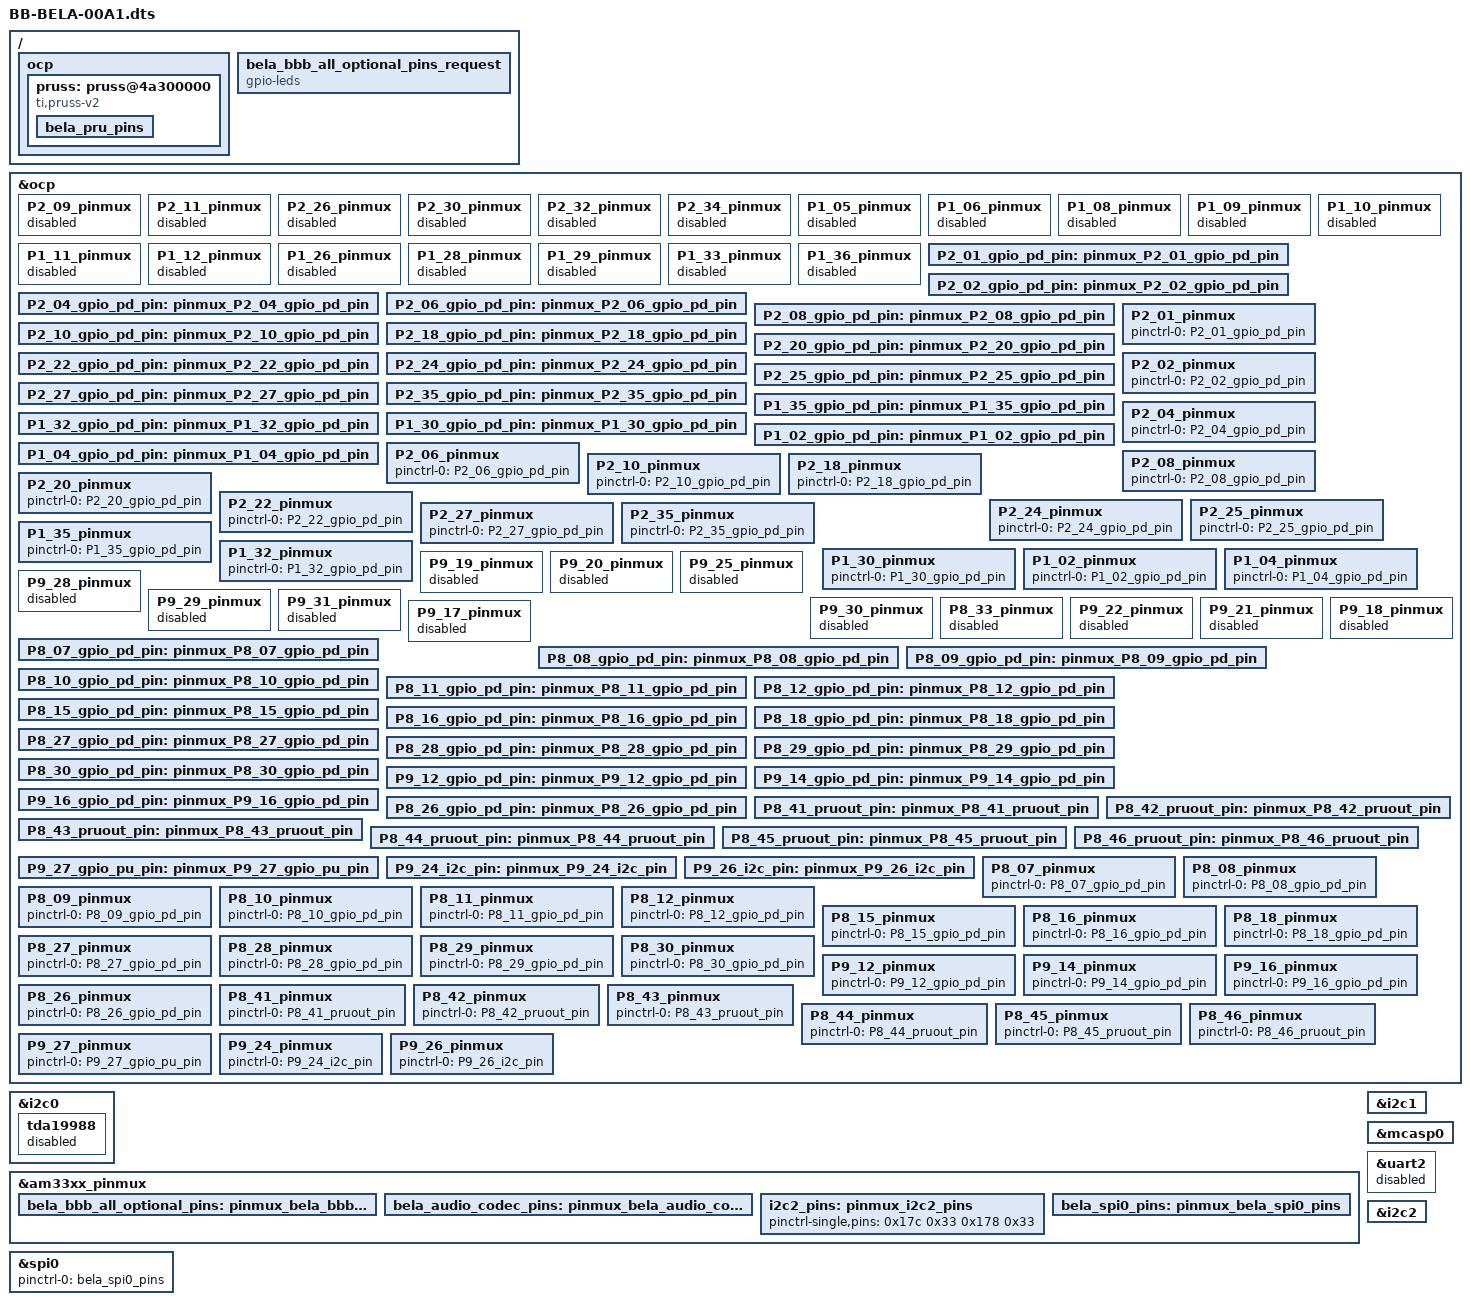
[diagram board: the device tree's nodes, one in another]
/*
 * Copyright (C) 2017-2018 <insert>
 *
 * This program is free software; you can redistribute it and/or modify
 * it under the terms of the GNU General Public License version 2 as
 * published by the Free Software Foundation.
 */

/dts-v1/;
/plugin/;

#include <dt-bindings/gpio/gpio.h>
#include <dt-bindings/pinctrl/am33xx.h>

/ {
	/*
	 * Free up the pins used by the cape from the pinmux helpers and set defaults
	 */
	fragment@0 {
		target = <&ocp>;
		__overlay__ {
			// PocketBeagle (has cape-universal built-in). If we
			// are on BBB, this fragment gets loaded but does
			// nothing.
			P2_09_pinmux { status = "disabled"; }; 
			P2_11_pinmux { status = "disabled"; }; 
			P2_26_pinmux { status = "disabled"; };
			P2_30_pinmux { status = "disabled"; };
			P2_32_pinmux { status = "disabled"; };
			P2_34_pinmux { status = "disabled"; };
			P1_05_pinmux { status = "disabled"; };
			P1_06_pinmux { status = "disabled"; };
			P1_08_pinmux { status = "disabled"; };
			P1_09_pinmux { status = "disabled"; };
			P1_10_pinmux { status = "disabled"; };
			P1_11_pinmux { status = "disabled"; };
			P1_12_pinmux { status = "disabled"; };
			P1_26_pinmux { status = "disabled"; };
			P1_28_pinmux { status = "disabled"; };
			P1_29_pinmux { status = "disabled"; };
			P1_33_pinmux { status = "disabled"; };
			P1_36_pinmux { status = "disabled"; };

			// these definitions copied from am335x-pocketbeagle-common.dtsi and are provided 
			// to avoid missing symbols when running on BBB
			P2_01_gpio_pd_pin: pinmux_P2_01_gpio_pd_pin { pinctrl-single,pins = <
				AM33XX_IOPAD(0x0848, PIN_OUTPUT_PULLDOWN | INPUT_EN | MUX_MODE7) >; };	/* gpmc_a2.gpio1_18 */
			P2_02_gpio_pd_pin: pinmux_P2_02_gpio_pd_pin { pinctrl-single,pins = <
				AM33XX_IOPAD(0x086c, PIN_OUTPUT_PULLDOWN | INPUT_EN | MUX_MODE7) >; };	/* gpmc_a11.gpio1_27 */
			P2_04_gpio_pd_pin: pinmux_P2_04_gpio_pd_pin { pinctrl-single,pins = <
				AM33XX_IOPAD(0x0868, PIN_OUTPUT_PULLDOWN | INPUT_EN | MUX_MODE7) >; };	/* gpmc_a10.gpio1_26 */
			P2_06_gpio_pd_pin: pinmux_P2_06_gpio_pd_pin { pinctrl-single,pins = <
				AM33XX_IOPAD(0x0864, PIN_OUTPUT_PULLDOWN | INPUT_EN | MUX_MODE7) >; };	/* gpmc_a9.gpio1_25 */
			P2_08_gpio_pd_pin: pinmux_P2_08_gpio_pd_pin { pinctrl-single,pins = <
				AM33XX_IOPAD(0x0878, PIN_OUTPUT_PULLDOWN | INPUT_EN | MUX_MODE7) >; };	/* gpmc_be1n.gpio1_28 */
			P2_10_gpio_pd_pin: pinmux_P2_10_gpio_pd_pin { pinctrl-single,pins = <
				AM33XX_IOPAD(0x0850, PIN_OUTPUT_PULLDOWN | INPUT_EN | MUX_MODE7) >; };	/* gpmc_a4.gpio1_20 */
			P2_18_gpio_pd_pin: pinmux_P2_18_gpio_pd_pin { pinctrl-single,pins = <
				AM33XX_IOPAD(0x083c, PIN_OUTPUT_PULLDOWN | INPUT_EN | MUX_MODE7) >; };	/* gpmc_ad15.gpio1_15 */
			P2_20_gpio_pd_pin: pinmux_P2_20_gpio_pd_pin { pinctrl-single,pins = <
				AM33XX_IOPAD(0x0888, PIN_OUTPUT_PULLDOWN | INPUT_EN | MUX_MODE7) >; };	/* gpmc_csn3.gpio2_0 */
			P2_22_gpio_pd_pin: pinmux_P2_22_gpio_pd_pin { pinctrl-single,pins = <
				AM33XX_IOPAD(0x0838, PIN_OUTPUT_PULLDOWN | INPUT_EN | MUX_MODE7) >; };	/* gpmc_ad14.gpio1_14 */
			P2_24_gpio_pd_pin: pinmux_P2_24_gpio_pd_pin { pinctrl-single,pins = <
				AM33XX_IOPAD(0x0830, PIN_OUTPUT_PULLDOWN | INPUT_EN | MUX_MODE7) >; };	/* gpmc_ad12.gpio1_12 */
			P2_25_gpio_pd_pin: pinmux_P2_25_gpio_pd_pin { pinctrl-single,pins = <
				AM33XX_IOPAD(0x096c, PIN_OUTPUT_PULLDOWN | INPUT_EN | MUX_MODE7) >; };	/* uart0_rtsn.gpio1_9 */
			P2_27_gpio_pd_pin: pinmux_P2_27_gpio_pd_pin { pinctrl-single,pins = <
				AM33XX_IOPAD(0x0968, PIN_OUTPUT_PULLDOWN | INPUT_EN | MUX_MODE7) >; };	/* uart0_ctsn.gpio1_8 */
			P2_35_gpio_pd_pin: pinmux_P2_35_gpio_pd_pin { pinctrl-single,pins = <
				AM33XX_IOPAD(0x08e0, PIN_OUTPUT_PULLDOWN | INPUT_EN | MUX_MODE7) >; };	/* lcd_vsync.gpio2_22 */
			P1_35_gpio_pd_pin: pinmux_P1_35_gpio_pd_pin { pinctrl-single,pins = <
				AM33XX_IOPAD(0x08e8, PIN_OUTPUT_PULLDOWN | INPUT_EN | MUX_MODE7) >; };	/* lcd_pclk.gpio2_24 */
			P1_32_gpio_pd_pin: pinmux_P1_32_gpio_pd_pin { pinctrl-single,pins = <
				AM33XX_IOPAD(0x0970, PIN_OUTPUT_PULLDOWN | INPUT_EN | MUX_MODE7) >; };	/* uart0_rxd.gpio1_10 */
			P1_30_gpio_pd_pin: pinmux_P1_30_gpio_pd_pin { pinctrl-single,pins = <
				AM33XX_IOPAD(0x0974, PIN_OUTPUT_PULLDOWN | INPUT_EN | MUX_MODE7) >; };	/* uart0_txd.gpio1_11 */
			P1_02_gpio_pd_pin: pinmux_P1_02_gpio_pd_pin { pinctrl-single,pins = <
				AM33XX_IOPAD(0x08e4, PIN_OUTPUT_PULLDOWN | INPUT_EN | MUX_MODE7) >; };	/* lcd_hsync.gpio2_23 */
			P1_04_gpio_pd_pin: pinmux_P1_04_gpio_pd_pin { pinctrl-single,pins = <
				AM33XX_IOPAD(0x08ec, PIN_OUTPUT_PULLDOWN | INPUT_EN | MUX_MODE7) >; };	/* lcd_ac_bias_en.gpio2_25 */

			// Bela digitals
			P2_01_pinmux{ pinctrl-0 = <&P2_01_gpio_pd_pin>; };
			P2_02_pinmux{ pinctrl-0 = <&P2_02_gpio_pd_pin>; };
			P2_04_pinmux{ pinctrl-0 = <&P2_04_gpio_pd_pin>; };
			P2_06_pinmux{ pinctrl-0 = <&P2_06_gpio_pd_pin>; };
			P2_08_pinmux{ pinctrl-0 = <&P2_08_gpio_pd_pin>; };
			P2_10_pinmux{ pinctrl-0 = <&P2_10_gpio_pd_pin>; };
			P2_18_pinmux{ pinctrl-0 = <&P2_18_gpio_pd_pin>; };
			P2_20_pinmux{ pinctrl-0 = <&P2_20_gpio_pd_pin>; };
			P2_22_pinmux{ pinctrl-0 = <&P2_22_gpio_pd_pin>; };
			P2_24_pinmux{ pinctrl-0 = <&P2_24_gpio_pd_pin>; };
			P2_25_pinmux{ pinctrl-0 = <&P2_25_gpio_pd_pin>; };
			P2_27_pinmux{ pinctrl-0 = <&P2_27_gpio_pd_pin>; };
			P2_35_pinmux{ pinctrl-0 = <&P2_35_gpio_pd_pin>; };
			P1_35_pinmux{ pinctrl-0 = <&P1_35_gpio_pd_pin>; };
			P1_32_pinmux{ pinctrl-0 = <&P1_32_gpio_pd_pin>; };
			P1_30_pinmux{ pinctrl-0 = <&P1_30_gpio_pd_pin>; };

			// LEDs
			P1_02_pinmux{ pinctrl-0 = <&P1_02_gpio_pd_pin>; };
			P1_04_pinmux{ pinctrl-0 = <&P1_04_gpio_pd_pin>; };
		};
	};
	fragment@1 {
		target = <&ocp>;
		__overlay__ {
			// BeagleBone when cape-universal is loaded. If it is not loaded, this fragment loads but does nothing.
			// When cape-universal* is not loaded, these pins are all set in bela_bbb_all_optional_pins

			// These are fixed function so we disable config-pin
			// and hardcode them elsewhere.
			P9_19_pinmux { status = "disabled"; }; // i2c2_scl
			P9_20_pinmux { status = "disabled"; }; // i2c2_sda
			P9_25_pinmux { status = "disabled"; }; // mcasp0_ahclkx
			P9_28_pinmux { status = "disabled"; }; // mcasp0_axr2
			P9_29_pinmux { status = "disabled"; }; // mcasp0_fsx
			P9_31_pinmux { status = "disabled"; }; // mcasp0_ahclk
			P9_30_pinmux { status = "disabled"; }; // mcasp0_axr0
			P8_33_pinmux { status = "disabled"; }; // mcasp0_axr3

			P9_22_pinmux { status = "disabled"; }; /* spi0_sclk */
			P9_21_pinmux { status = "disabled"; }; /* spi0_d0 */
			P9_18_pinmux { status = "disabled"; }; /* spi0_d1 */
			P9_17_pinmux { status = "disabled"; }; // spi0_cs0

			// For the below, if cape-universal* is loaded, we set
			// here the default value, but users can override it
			// with config-pin.

			//These definitions are copied from
			//cape-universaln-00A0.dts and are provided to avoid
			//missing symbols when cape-universaln is not loaded

			P8_07_gpio_pd_pin: pinmux_P8_07_gpio_pd_pin { pinctrl-single,pins = <
				AM33XX_IOPAD(0x0890, PIN_OUTPUT_PULLDOWN | INPUT_EN | MUX_MODE7) >; };	/* gpmc_advn_ale.gpio2_2 */
			P8_08_gpio_pd_pin: pinmux_P8_08_gpio_pd_pin { pinctrl-single,pins = <
				AM33XX_IOPAD(0x0894, PIN_OUTPUT_PULLDOWN | INPUT_EN | MUX_MODE7) >; };	/* gpmc_oen_ren.gpio2_3 */
			P8_09_gpio_pd_pin: pinmux_P8_09_gpio_pd_pin { pinctrl-single,pins = <
				AM33XX_IOPAD(0x089c, PIN_OUTPUT_PULLDOWN | INPUT_EN | MUX_MODE7) >; };	/* gpmc_be0n_cle.gpio2_5 */
			P8_10_gpio_pd_pin: pinmux_P8_10_gpio_pd_pin { pinctrl-single,pins = <
				AM33XX_IOPAD(0x0898, PIN_OUTPUT_PULLDOWN | INPUT_EN | MUX_MODE7) >; };	/* gpmc_wen.gpio2_4 */
			P8_11_gpio_pd_pin: pinmux_P8_11_gpio_pd_pin { pinctrl-single,pins = <
				AM33XX_IOPAD(0x0834, PIN_OUTPUT_PULLDOWN | INPUT_EN | MUX_MODE7) >; };	/* gpmc_ad13.gpio1_13 */
			P8_12_gpio_pd_pin: pinmux_P8_12_gpio_pd_pin { pinctrl-single,pins = <
				AM33XX_IOPAD(0x0830, PIN_OUTPUT_PULLDOWN | INPUT_EN | MUX_MODE7) >; };	/* gpmc_ad12.gpio1_12 */
			P8_15_gpio_pd_pin: pinmux_P8_15_gpio_pd_pin { pinctrl-single,pins = <
				AM33XX_IOPAD(0x083c, PIN_OUTPUT_PULLDOWN | INPUT_EN | MUX_MODE7) >; };	/* gpmc_ad15.gpio1_15 */
			P8_16_gpio_pd_pin: pinmux_P8_16_gpio_pd_pin { pinctrl-single,pins = <
				AM33XX_IOPAD(0x0838, PIN_OUTPUT_PULLDOWN | INPUT_EN | MUX_MODE7) >; };	/* gpmc_ad14.gpio1_14 */
			P8_18_gpio_pd_pin: pinmux_P8_18_gpio_pd_pin { pinctrl-single,pins = <
				AM33XX_IOPAD(0x088c, PIN_OUTPUT_PULLDOWN | INPUT_EN | MUX_MODE7) >; };	/* gpmc_clk.gpio2_1 */
			P8_27_gpio_pd_pin: pinmux_P8_27_gpio_pd_pin { pinctrl-single,pins = <
				AM33XX_IOPAD(0x08e0, PIN_OUTPUT_PULLDOWN | INPUT_EN | MUX_MODE7) >; };	/* lcd_vsync.gpio2_22 */
			P8_28_gpio_pd_pin: pinmux_P8_28_gpio_pd_pin { pinctrl-single,pins = <
				AM33XX_IOPAD(0x08e8, PIN_OUTPUT_PULLDOWN | INPUT_EN | MUX_MODE7) >; };	/* lcd_pclk.gpio2_24 */
			P8_29_gpio_pd_pin: pinmux_P8_29_gpio_pd_pin { pinctrl-single,pins = <
				AM33XX_IOPAD(0x08e4, PIN_OUTPUT_PULLDOWN | INPUT_EN | MUX_MODE7) >; };	/* lcd_hsync.gpio2_23 */
			P8_30_gpio_pd_pin: pinmux_P8_30_gpio_pd_pin { pinctrl-single,pins = <
				AM33XX_IOPAD(0x08ec, PIN_OUTPUT_PULLDOWN | INPUT_EN | MUX_MODE7) >; };	/* lcd_ac_bias_en.gpio2_25 */
			P9_12_gpio_pd_pin: pinmux_P9_12_gpio_pd_pin { pinctrl-single,pins = <
				AM33XX_IOPAD(0x0878, PIN_OUTPUT_PULLDOWN | INPUT_EN | MUX_MODE7) >; };	/* gpmc_be1n.gpio1_28 */
			P9_14_gpio_pd_pin: pinmux_P9_14_gpio_pd_pin { pinctrl-single,pins = <
				AM33XX_IOPAD(0x0848, PIN_OUTPUT_PULLDOWN | INPUT_EN | MUX_MODE7) >; };	/* gpmc_a2.gpio1_18 */
			P9_16_gpio_pd_pin: pinmux_P9_16_gpio_pd_pin { pinctrl-single,pins = <
				AM33XX_IOPAD(0x084c, PIN_OUTPUT_PULLDOWN | INPUT_EN | MUX_MODE7) >; };	/* gpmc_a3.gpio1_19 */
			P8_26_gpio_pd_pin: pinmux_P8_26_gpio_pd_pin { pinctrl-single,pins = <
				AM33XX_IOPAD(0x087c, PIN_OUTPUT_PULLDOWN | INPUT_EN | MUX_MODE7) >; };	/* gpmc_csn0.gpio1_29 */
			P8_41_pruout_pin: pinmux_P8_41_pruout_pin { pinctrl-single,pins = <
				AM33XX_IOPAD(0x08b0, PIN_OUTPUT_PULLDOWN | INPUT_EN | MUX_MODE5) >; };	/* lcd_data4.pru1_out4 */
			P8_42_pruout_pin: pinmux_P8_42_pruout_pin { pinctrl-single,pins = <
				AM33XX_IOPAD(0x08b4, PIN_OUTPUT_PULLDOWN | INPUT_EN | MUX_MODE5) >; };	/* lcd_data5.pru1_out5 */
			P8_43_pruout_pin: pinmux_P8_43_pruout_pin { pinctrl-single,pins = <
				AM33XX_IOPAD(0x08a8, PIN_OUTPUT_PULLDOWN | INPUT_EN | MUX_MODE5) >; };	/* lcd_data2.pru1_out2 */
			P8_44_pruout_pin: pinmux_P8_44_pruout_pin { pinctrl-single,pins = <
				AM33XX_IOPAD(0x08ac, PIN_OUTPUT_PULLDOWN | INPUT_EN | MUX_MODE5) >; };	/* lcd_data3.pru1_out3 */
			P8_45_pruout_pin: pinmux_P8_45_pruout_pin { pinctrl-single,pins = <
				AM33XX_IOPAD(0x08a0, PIN_OUTPUT_PULLDOWN | INPUT_EN | MUX_MODE5) >; };	/* lcd_data0.pru1_out0 */
			P8_46_pruout_pin: pinmux_P8_46_pruout_pin { pinctrl-single,pins = <
				AM33XX_IOPAD(0x08a4, PIN_OUTPUT_PULLDOWN | INPUT_EN | MUX_MODE5) >; };	/* lcd_data1.pru1_out1 */
			P9_27_gpio_pu_pin: pinmux_P9_27_gpio_pu_pin { pinctrl-single,pins = <
				AM33XX_IOPAD(0x09a4, PIN_OUTPUT_PULLUP | INPUT_EN | MUX_MODE7) >; };	/* mcasp0_fsr.gpio3_19 */
			P9_24_i2c_pin: pinmux_P9_24_i2c_pin { pinctrl-single,pins = <
				AM33XX_IOPAD(0x0984, PIN_OUTPUT_PULLUP | INPUT_EN | MUX_MODE3) >; };	/* uart1_txd.i2c1_scl */
			P9_26_i2c_pin: pinmux_P9_26_i2c_pin { pinctrl-single,pins = <
				AM33XX_IOPAD(0x0980, PIN_OUTPUT_PULLUP | INPUT_EN | MUX_MODE3) >; };	/* uart1_rxd.i2c1_sda */

			// Bela digitals
			P8_07_pinmux { pinctrl-0 = <&P8_07_gpio_pd_pin>; };
			P8_08_pinmux { pinctrl-0 = <&P8_08_gpio_pd_pin>; };
			P8_09_pinmux { pinctrl-0 = <&P8_09_gpio_pd_pin>; };
			P8_10_pinmux { pinctrl-0 = <&P8_10_gpio_pd_pin>; };
			P8_11_pinmux { pinctrl-0 = <&P8_11_gpio_pd_pin>; };
			P8_12_pinmux { pinctrl-0 = <&P8_12_gpio_pd_pin>; };
			P8_15_pinmux { pinctrl-0 = <&P8_15_gpio_pd_pin>; };
			P8_16_pinmux { pinctrl-0 = <&P8_16_gpio_pd_pin>; };
			P8_18_pinmux { pinctrl-0 = <&P8_18_gpio_pd_pin>; };
			P8_27_pinmux { pinctrl-0 = <&P8_27_gpio_pd_pin>; };
			P8_28_pinmux { pinctrl-0 = <&P8_28_gpio_pd_pin>; };
			P8_29_pinmux { pinctrl-0 = <&P8_29_gpio_pd_pin>; };
			P8_30_pinmux { pinctrl-0 = <&P8_30_gpio_pd_pin>; };
			P9_12_pinmux { pinctrl-0 = <&P9_12_gpio_pd_pin>; };
			P9_14_pinmux { pinctrl-0 = <&P9_14_gpio_pd_pin>; };
			P9_16_pinmux { pinctrl-0 = <&P9_16_gpio_pd_pin>; };

			P8_26_pinmux { pinctrl-0 = <&P8_26_gpio_pd_pin>; }; // speaker mute pin
			P8_41_pinmux { pinctrl-0 = <&P8_41_pruout_pin>; }; // muxer clock
			P8_42_pinmux { pinctrl-0 = <&P8_42_pruout_pin>; }; // muxer clock
			P8_43_pinmux { pinctrl-0 = <&P8_43_pruout_pin>; }; // muxer clock
			P8_44_pinmux { pinctrl-0 = <&P8_44_pruout_pin>; }; // muxer clock
			P8_45_pinmux { pinctrl-0 = <&P8_45_pruout_pin>; }; // muxer clock
			P8_46_pinmux { pinctrl-0 = <&P8_46_pruout_pin>; }; // muxer clock
			P9_27_pinmux { pinctrl-0 = <&P9_27_gpio_pu_pin>; }; // Bela Button
			P9_24_pinmux { pinctrl-0 = <&P9_24_i2c_pin>; }; // i2c1_scl
			P9_26_pinmux { pinctrl-0 = <&P9_26_i2c_pin>; }; // i2c1_sda
		};
	};

	fragment@2 {
		// disable HDMI
		target = <&i2c0>;
		__overlay__ {
			tda19988 {
				status = "disabled";
			};
		};
	};

	fragment@3 {
		// this fragment only contains definitions so it will always load
		// These definitions are for BBB without cape-universal
		target = <&am33xx_pinmux>;
		__overlay__ {
			bela_bbb_all_optional_pins: pinmux_bela_bbb_all_optional_pins {
				pinctrl-single,pins = <
					/* Pinmux for PRU */
					0x0b0 0x25 /* pr1_pru1_pru_r30_4, 	P8_41 | MODE5 | INPUT_PULLDOWN */
					0x0b4 0x25 /* pr1_pru1_pru_r30_5, 	P8_42 | MODE5 | INPUT_PULLDOWN */
					0x0ac 0x25 /* pr1_pru1_pru_r30_3, 	P8_44 | MODE5 | INPUT_PULLDOWN */
					0x0a0 0x25 /* pr1_pru1_pru_r30_0, 	P8_45 | MODE5 | INPUT_PULLDOWN */
					0x0a4 0x25 /* pr1_pru1_pru_r30_1, 	P8_46 | MODE5 | INPUT_PULLDOWN */
					0x0a8 0x25 /* pr1_pru1_pru_r30_2, 	P8_43 | MODE5 | INPUT_PULLDOWN */

					/* The Bela Button */
					0x1a4 0x37 /* gpio3[19], 			P9_27 | MODE7 | INPUT_PULLUP */

					/* Pinmux for i2c1 on Bela header */
					0x180 0x33 /* i2c1_sda, 	P9_26 | MODE3 | INPUT_PULLUP */
					0x184 0x33 /* i2c1_scl,		P9_24 | MODE3 | INPUT_PULLUP */

					/* Pinmux for GPIO (digital i/o) */
					0x090 0x27 /* gpio2[2], 			P8_07 | MODE7 | INPUT_PULLDOWN */
					0x094 0x27 /* gpio2[3], 			P8_08 | MODE7 | INPUT_PULLDOWN */
					0x09c 0x27 /* gpio2[5], 			P8_09 | MODE7 | INPUT_PULLDOWN */
					0x098 0x27 /* gpio2[4], 			P8_10 | MODE7 | INPUT_PULLDOWN */
					0x034 0x27 /* gpio1[13],			P8_11 | MODE7 | INPUT_PULLDOWN */
					0x030 0x27 /* gpio2[13],			P8_12 | MODE7 | INPUT_PULLDOWN */
					0x078 0x27 /* gpio1[28],			P9_12 | MODE7 | INPUT_PULLDOWN */
					0x048 0x27 /* gpio1[18],			P9_14 | MODE7 | INPUT_PULLDOWN */
					0x03c 0x27 /* gpio1[15],			P8_15 | MODE7 | INPUT_PULLDOWN */
					0x038 0x27 /* gpio1[14], 			P8_16 | MODE7 | INPUT_PULLDOWN */
					0x04c 0x27 /* gpio1[19],			P9_16 | MODE7 | INPUT_PULLDOWN */
					0x08c 0x27 /* gpio2[1], 			P8_18 | MODE7 | INPUT_PULLDOWN */
					0x0e0 0x27 /* gpio2[22],			P8_27 | MODE7 | INPUT_PULLDOWN */
					0x0e8 0x27 /* gpio2[24],			P8_28 | MODE7 | INPUT_PULLDOWN */
					0x0e4 0x27 /* gpio2[23],			P8_29 | MODE7 | INPUT_PULLDOWN */
					0x0ec 0x27 /* gpio2[25],			P8_30 | MODE7 | INPUT_PULLDOWN */
				>;
			};	
		};
	};

	fragment@4 {
		// Definition of pins for BBB (with or without cape-universal)
		target = <&am33xx_pinmux>;
		__overlay__ {
			/* Pinmux for McASP0 (audio i/o) */
			bela_audio_codec_pins: pinmux_bela_audio_codec_pins {
				pinctrl-single,pins = <
					0x1ac 0x00 /* mcasp0_ahclkx, 		P9_25 | MODE0 | OUTPUT_PULLDOWN */
					0x19c 0x22 /* mcasp0_axr2, 			P9_28 | MODE2 | INPUT_PULLDOWN */
					0x194 0x20 /* mcasp0_fsx, 			P9_29 | MODE0 | INPUT_PULLDOWN */
					0x190 0x20 /* mcasp0_aclkx, 		P9_31 | MODE0 | INPUT_PULLDOWN */
					0x198 0x20 /* mcasp0_axr0, 			P9_30 | MODE0 | INPUT_PULLDOWN */
					0x0d4 0x24 /* mcasp0_axr3, 			P8_33 | MODE0 | INPUT_PULLDOWN */
				>;
			};

			// Pinmux for i2c2 for Bela codec
			i2c2_pins: pinmux_i2c2_pins {
				pinctrl-single,pins = <
					0x17c 0x33 // i2c2_scl | P9.20/P1.28 | MODE3 | INPUT_PULLUP
					0x178 0x33 // i2c2_sda | P9.19/P1.26 | MODE3 | INPUT_PULLUP
				>;
			};

			/* Pinmux for McSPI0 (analog i/o) */
			bela_spi0_pins: pinmux_bela_spi0_pins {
				pinctrl-single,pins = <
					0x150 0x30 /* spi0_sclk, 			P9_22 | MODE0 | INPUT_PULLUP */
					0x154 0x30 /* spi0_d0, 				P9_21 | MODE0 | INPUT_PULLUP */
					0x158 0x10 /* spi0_d1, 				P9_18 | MODE0 | OUTPUT_PULLUP */
					0x15c 0x27 /* spi0_cs0, 			P9_17 | MODE0 | OUTPUT_PULLUP */
				>;
			};
		};
	};

	fragment@5 {
		target = <&i2c1>;
		__overlay__ {
			pinctrl-names = "default";
			pinctrl-0 = <>; // pins are set elsewhere

			status = "okay";
			clock-frequency = <400000>;
		};
	};

	/* McASP config */
	fragment@6 {
		target = <&mcasp0>;
		__overlay__ {
			pinctrl-names = "default";
			pinctrl-0 = <&bela_audio_codec_pins>;
			pinctrl-1 = <>; // pins are set elsewhere

			status = "okay";
			interrupt-names = "dummytx", "dummyrx";

			op-mode = <0>;	// MCASP_IIS_MODE
			tdm-slots = <2>;
			num-serializer = <16>;
			serial-dir = <  // 0: INACTIVE, 1: TX, 2: RX
				2 0 1 0
				0 0 0 0
				0 0 0 0
				0 0 0 0
			>;
			tx-num-evt = <1>;
			rx-num-evt = <1>;
		};
	};

	/* PRU config */
	fragment@7 {
		target-path="/";
		__overlay__ {
			ocp {
				#address-cells = <1>;
				#size-cells = <1>;

				pruss: pruss@4a300000 {
					status = "okay";
					compatible = "ti,pruss-v2";
					ti,hwmods = "pruss";
					ti,deassert-hard-reset = "pruss", "pruss";
					reg = <0x4a300000 0x080000>;
					ti,pintc-offset = <0x20000>;
					interrupt-parent = <&intc>;
					interrupts = <20 21 22 23 24 25 26 27>;

					pinctrl-names = "default";
					pinctrl-0 = <>; // pins are set elsewhere

					/* Workaround for uio_pruss.c on 4.4.62 to prevent "No Children" error */
					bela_pru_pins {
						pin-names = "dummy";
						gpios = <&gpio1 1 2>;
						#gpio-cells = <2>;
					};
				};
			};
		};
	};

	fragment@8 { // this is only needed by BBG, where uart2 is enabled, and its pins conflict with our spi0
		target = <&uart2>;
		__overlay__ {
			status = "disabled";
		};
	};

	fragment@9 {
		target = <&spi0>;
		__overlay__ {
			pinctrl-names = "default";
			pinctrl-0 = <&bela_spi0_pins>;

			status = "okay";
		};
	};

	fragment@10 {
		// Setting optional pins for BBB (without cape-universal)
		target-path="/";
		__overlay__ {
			// this will fail on PB and on BB with cape universal
			bela_bbb_all_optional_pins_request {
				compatible = "gpio-leds";
				pinctrl-0 = <&bela_bbb_all_optional_pins>;
				pinctrl-1 = <>;
				pinctrl-names = "default", "sleep";
			};
		};
	};
			
	fragment@11 {

		target = <&i2c2>;
		__overlay__ {
			pinctrl-names = "default";
			pinctrl-0 = <&i2c2_pins>;

			status = "okay";
			clock-frequency = <400000>;
		};

	};
#if 0
	fragment@12 {
		target = <&am33xx_pinmux>;
		__overlay__ {
			P9_24_bela: pinmux_default_bela_P9_24 { pinctrl-single,pins = <0x184 0x33>; };
		};
	};
#endif
};
